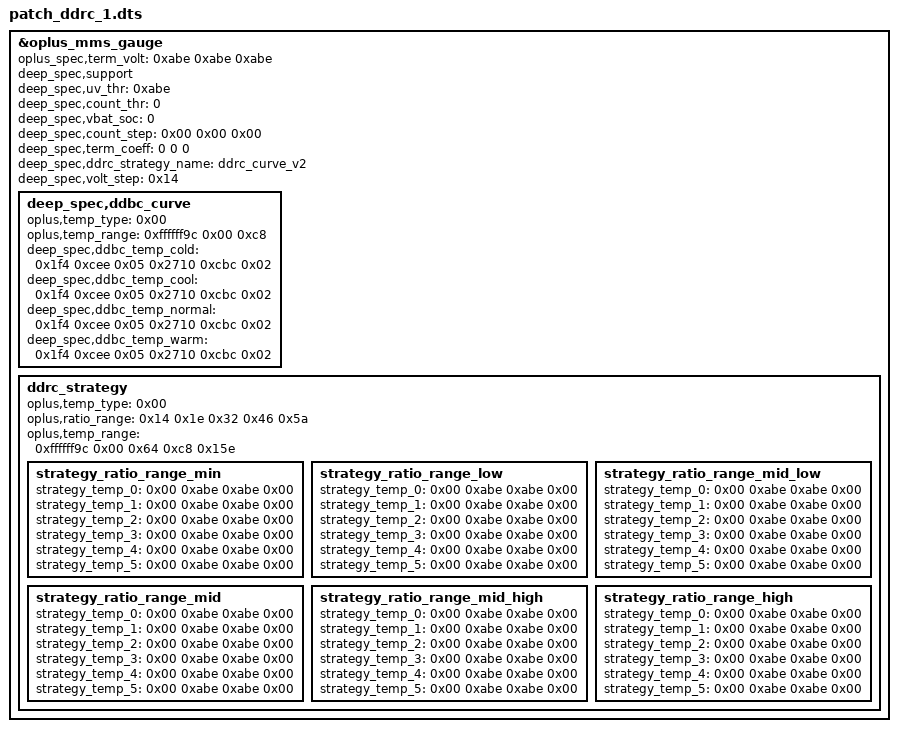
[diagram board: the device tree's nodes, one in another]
/dts-v1/;
/plugin/;

/ {
	fragment@0 {
		target = <&oplus_mms_gauge>;
		__overlay__ {
			oplus_spec,term_volt = <0xabe 0xabe 0xabe>;
			deep_spec,support;
			deep_spec,uv_thr = <0xabe>;
			deep_spec,count_thr = <0>;
			deep_spec,vbat_soc = <0>;
			deep_spec,count_step = <0x00 0x00 0x00>;
			deep_spec,term_coeff = <0 0 0>;
			deep_spec,ddrc_strategy_name = "ddrc_curve_v2";
			deep_spec,volt_step = <0x14>;
			
			deep_spec,ddbc_curve {
				oplus,temp_type = <0x00>;
				oplus,temp_range = <0xffffff9c 0x00 0xc8>;
				deep_spec,ddbc_temp_cold = <0x1f4 0xcee 0x05 0x2710 0xcbc 0x02>;
				deep_spec,ddbc_temp_cool = <0x1f4 0xcee 0x05 0x2710 0xcbc 0x02>;
				deep_spec,ddbc_temp_normal = <0x1f4 0xcee 0x05 0x2710 0xcbc 0x02>;
				deep_spec,ddbc_temp_warm = <0x1f4 0xcee 0x05 0x2710 0xcbc 0x02>;
			};
			ddrc_strategy {
				oplus,temp_type = <0x00>;
				oplus,ratio_range = <0x14 0x1e 0x32 0x46 0x5a>;
				oplus,temp_range = <0xffffff9c 0x00 0x64 0xc8 0x15e>;
				
				strategy_ratio_range_min {
					strategy_temp_0 = <0x00 0xabe 0xabe 0x00>;
					strategy_temp_1 = <0x00 0xabe 0xabe 0x00>;
					strategy_temp_2 = <0x00 0xabe 0xabe 0x00>;
					strategy_temp_3 = <0x00 0xabe 0xabe 0x00>;
					strategy_temp_4 = <0x00 0xabe 0xabe 0x00>;
					strategy_temp_5 = <0x00 0xabe 0xabe 0x00>;
				};
				
				strategy_ratio_range_low {
					strategy_temp_0 = <0x00 0xabe 0xabe 0x00>;
					strategy_temp_1 = <0x00 0xabe 0xabe 0x00>;
					strategy_temp_2 = <0x00 0xabe 0xabe 0x00>;
					strategy_temp_3 = <0x00 0xabe 0xabe 0x00>;
					strategy_temp_4 = <0x00 0xabe 0xabe 0x00>;
					strategy_temp_5 = <0x00 0xabe 0xabe 0x00>;
				};
				
				strategy_ratio_range_mid_low {
					strategy_temp_0 = <0x00 0xabe 0xabe 0x00>;
					strategy_temp_1 = <0x00 0xabe 0xabe 0x00>;
					strategy_temp_2 = <0x00 0xabe 0xabe 0x00>;
					strategy_temp_3 = <0x00 0xabe 0xabe 0x00>;
					strategy_temp_4 = <0x00 0xabe 0xabe 0x00>;
					strategy_temp_5 = <0x00 0xabe 0xabe 0x00>;
				};
				
				strategy_ratio_range_mid {
					strategy_temp_0 = <0x00 0xabe 0xabe 0x00>;
					strategy_temp_1 = <0x00 0xabe 0xabe 0x00>;
					strategy_temp_2 = <0x00 0xabe 0xabe 0x00>;
					strategy_temp_3 = <0x00 0xabe 0xabe 0x00>;
					strategy_temp_4 = <0x00 0xabe 0xabe 0x00>;
					strategy_temp_5 = <0x00 0xabe 0xabe 0x00>;
				};
				
				strategy_ratio_range_mid_high {
					strategy_temp_0 = <0x00 0xabe 0xabe 0x00>;
					strategy_temp_1 = <0x00 0xabe 0xabe 0x00>;
					strategy_temp_2 = <0x00 0xabe 0xabe 0x00>;
					strategy_temp_3 = <0x00 0xabe 0xabe 0x00>;
					strategy_temp_4 = <0x00 0xabe 0xabe 0x00>;
					strategy_temp_5 = <0x00 0xabe 0xabe 0x00>;
				};
				
				strategy_ratio_range_high {
					strategy_temp_0 = <0x00 0xabe 0xabe 0x00>;
					strategy_temp_1 = <0x00 0xabe 0xabe 0x00>;
					strategy_temp_2 = <0x00 0xabe 0xabe 0x00>;
					strategy_temp_3 = <0x00 0xabe 0xabe 0x00>;
					strategy_temp_4 = <0x00 0xabe 0xabe 0x00>;
					strategy_temp_5 = <0x00 0xabe 0xabe 0x00>;
				};
			};
		};
	};
};
